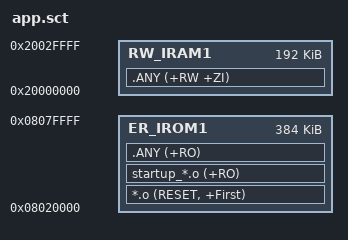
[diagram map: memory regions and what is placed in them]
; *************************************************************
; *** Scatter-Loading Description File — App ***
; *** STM32F429IGTx App 384KB (0x08020000-0x0807FFFF)      ***
; *************************************************************

LR_IROM1 0x08020000 0x00060000  {    ; 加载区：App A 384KB
  ER_IROM1 0x08020000 0x00060000  {  ; 执行区
   *.o (RESET, +First)
   startup_*.o (+RO)
   .ANY (+RO)
  }
  RW_IRAM1 0x20000000 0x00030000  {  ; 192KB SRAM
   .ANY (+RW +ZI)
  }
}
